# M0564AE_v1 register map
File version: 1.0
Registers are 32-bit, read-write, reset 0x0 unless marked. A register's access mark holds for its fields unless they carry their own. Offsets are from the block's base; [hi:lo] are bit positions.

## SC0 — SC Register Map
Base 0x40190000
Same registers: SC1 0x40194000
0x00 SC_DAT reset not defined — SC Receive/Transmit Holding Buffer Register
  [7:0] DAT — Receive/Transmit Holding Buffer. Write Operation: By writing data to DAT, the SC will send out an 8-bit data. Read Operation: By reading DAT, the SC will return an 8-bit received data. Note: If SCEN (SC_CTL[0]) is not enabled, DAT cannot be programmed.
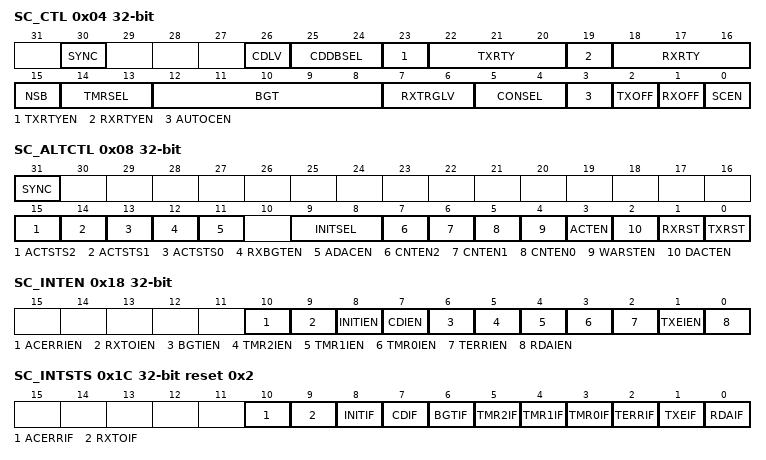
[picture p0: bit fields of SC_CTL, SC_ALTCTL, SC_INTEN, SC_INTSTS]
0x04 SC_CTL — SC Control Register
  [30] SYNC ro — SYNC Flag Indicator (Read Only). Due to synchronization, user should check this bit before writing a new value to RXRTY and TXRTY fields.
    0=Synchronizing is completion, user can write new data to RXRTY and TXRTY; 1=Last value is synchronizing
  [26] CDLV — Card Detect Level Selection. Note: User must select card detect level before Smart Card controller enabled.
    0=When hardware detects the card detect pin (SC_CD) from high to low, it indicates a card is detected; 1=When hardware detects the card detect pin (SC_CD) from low to high, it indicates a card is detected
  [25:24] CDDBSEL — Card Detect De-bounce Selection. This field indicates the card detect de-bounce selection. Other configurations are reserved.
    0=De-bounce sample card insert once per 384 (128 * 3) SC modue clocks and de-bounce sample card removal once per 128 SC modue clocks
  [23] TXRTYEN — TX Error Retry Enable Bit. This bit enables transmitter retry function when parity error has occurred.
    0=TX error retry function Disabled; 1=TX error retry function Enabled
  [22:20] TXRTY — TX Error Retry Count Number. This field indicates the maximum number of transmitter retries that are allowed when parity error has occurred. Note1: The real retry number is TXRTY + 1, so 8 is the maximum retry number. Note2: This field cannot be changed when TXRTYEN enabled. The change flow is to disable TXRTYEN first and then fill in new retry value.
  [19] RXRTYEN — RX Error Retry Enable Bit. This bit enables receiver retry function when parity error has occurred. Note: User must fill in the RXRTY value before enabling this bit.
    0=RX error retry function Disabled; 1=RX error retry function Enabled
  [18:16] RXRTY — RX Error Retry Count Number. This field indicates the maximum number of receiver retries that are allowed when parity error has occurred. Note1: The real retry number is RXRTY + 1, so 8 is the maximum retry number. Note2: This field cannot be changed when RXRTYEN enabled. The change flow is to disable RXRTYEN first and then fill in new retry value.
  [15] NSB — Stop Bit Length. This field indicates the length of stop bit. Note1: The default stop bit length is 2. SC and UART adopts NSB to program the stop bit length. Note2: In UART mode, RX can receive the data sequence in 1 stop bit or 2 stop bits with NSB is set to 0.
    0=The stop bit length is 2 ETU; 1=The stop bit length is 1 ETU
  [14:13] TMRSEL — Timer Channel Selection. Other configurations are reserved
    0=All internal timer function Disabled; 3=Internal 24-bit Timer0 and two 8-bit Timer0 and Timer1 are enabled. User can configure them by setting SC_TMRCTL0[23:0], SC_TMRCTL1[7:0] and SC_TMRCTL2[7:0]
  [12:8] BGT — Block Guard Time (BGT). Note: The real block guard time is BGT + 1.
  [7:6] RXTRGLV — Rx Buffer Trigger Level. When the number of bytes in the receiving buffer equals the RXTRGLV, the RDAIF (SC_INTSTS[0]) will be set. If RDAIEN (SC_INTEN[0]) is enabled, an interrupt signal will be generated to inform CPU.
    0=Rx Buffer Trigger Level with 01 bytes; 1=Rx Buffer Trigger Level with 02 bytes; 2=Rx Buffer Trigger Level with 03 bytes
  [5:4] CONSEL — Convention Selection. Note: If AUTOCEN (SC_CTL[3]) is enabled, this field is ignored.
    0=Direct convention; 3=Inverse convention
  [3] AUTOCEN — Auto Convention Enable Bit. This bit is used to enable auto convention function. Note1: If user enables auto convention function, the setting step must be done before Answer to Reset (ATR) state and the first data must be 0x3B or 0x3F. After hardware received first data and stored it at buffer, hardware will decided the convention and change the CONSEL (SC_CTL[5:4]) bits automatically when received first data is 0x3B or 0x3F. If received first byte is 0x3B, TS is direct convention, CONSEL (SC_CTL[5:4]) will be set to 00 automatically, otherwise the TS is inverse convention, and CONSEL (SC_CTL[5:4]) will be set to 11. Note2: If the first data is not 0x3B or 0x3F, hardware will set ACERRIF (SC_INTSTS[10]) and generate an interrupt signal to inform CPU when ACERRIEN (SC_INTEN[10]) is enabled.
    0=Auto-convention Disabled; 1=Auto-convention Enabled
  [2] TXOFF — TX Transition Disable Bit. This bit is used to disable Tx transmit function.
    0=The transceiver Enabled; 1=The transceiver Disabled
  [1] RXOFF — RX Transition Disable Bit. This bit is used to disable Rx receive function. Note: If AUTOCEN (SC_CTL[3]) is enabled, this field is ignored.
    0=The receiver Enabled; 1=The receiver Disabled
  [0] SCEN — SC Controller Enable Bit. Set this bit to 1 to enable SC operation function. Note: SCEN must be set to 1 before filling in other SC registers, or smart card will not work properly.
    0=SC will force all transition to IDLE state; 1=SC controller is enabled and all function can work correctly
0x08 SC_ALTCTL — SC Alternate Control Register
  [31] SYNC ro — SYNC Flag Indicator (Read Only). Due to synchronization, user should check this bit when writing a new value to SC_ALTCTL register.
    0=Synchronizing is completion, user can write new data to SC_ALTCTL register; 1=Last value is synchronizing
  [15] ACTSTS2 ro — Internal Timer2 Active Status (Read Only). This bit indicates the timer counter status of timer2. Note: Timer2 is active does not always mean timer2 is counting the CNT (SC_TMRCTL2[7:0]).
    0=Timer2 is not active; 1=Timer2 is active
  [14] ACTSTS1 ro — Internal Timer1 Active Status (Read Only). This bit indicates the timer counter status of timer1. Note: Timer1 is active does not always mean timer1 is counting the CNT (SC_TMRCTL1[7:0]).
    0=Timer1 is not active; 1=Timer1 is active
  [13] ACTSTS0 ro — Internal Timer0 Active Status (Read Only). This bit indicates the timer counter status of timer0. Note: Timer0 is active does not always mean timer0 is counting the CNT (SC_TMRCTL0[23:0]).
    0=Timer0 is not active; 1=Timer0 is active
  [12] RXBGTEN — Receiver Block Guard Time Function Enable Bit. This bit enables the receiver block guard time function.
    0=Receiver block guard time function Disabled; 1=Receiver block guard time function Enabled
  [11] ADACEN — Auto Deactivation When Card Removal. This bit is usde for enable hardware auto deactivation when smart card is removed. Note: When the card is removed, hardware will stop any process and then do deactivation sequence if this bit is set. If auto deactivation process completes, hardware will set INITIF (SC_INTSTS[8]) also.
    0=Auto deactivation Disabled; 1=Auto deactivation Enabled
  [9:8] INITSEL — Initial Timing Selection. This fields indicates the initial timing of hardware activation, warm-reset or deactivation. The unit of initial timing is SC module clock. Activation: refer to SC Activation Sequence in Figure 6.154. Warm-reset: refer to Warm-Reset Sequence in Figure 6.155. Deactivation: refer to Deactivation Sequence in Figure 6.156. Note: When setting activation and warm reset in Timer0 operation mode 0011, it may have deviation at most 128 SC module clock cycles.
  [7] CNTEN2 — Internal Timer2 Start Enable Bit. This bit enables Timer 2 to start counting. User can fill 0 to stop count and set 1 to reload and start count. The counter unit is ETU base. Note3: If SCEN (SC_CTL[0]) is not enabled, this filed cannot be programmed.
    0=Stop counting; 1=Start counting
  [6] CNTEN1 — Internal Timer1 Start Enable Bit. This bit enables Timer 1 to start counting. User can fill 0 to stop count and set 1 to reload and start count. The counter unit is ETU base. Note3: If SCEN (SC_CTL[0]) is not enabled, this filed cannot be programmed.
    0=Stop counting; 1=Start counting
  [5] CNTEN0 — Internal Timer0 Start Enable Bit. This bit enables Timer 0 to start counting. User can fill 0 to stop count and set 1 to reload and start count. The counter unit is ETU base. Note3: If SCEN (SC_CTL[0]) is not enabled, this filed cannot be programmed.
    0=Stop counting; 1=Start counting
  [4] WARSTEN — Warm Reset Sequence Generator Enable Bit. This bit enables SC controller to initiate the card by warm reset sequence. Note1: When the warm reset sequence completed, this bit will be cleared automatically and the INITIF (SC_INTSTS[8]) will be set to 1. Note2: This field will be cleared by set TXRST (SC_ALTCTL[0]) or RXRST (SC_ALTCTL[1]). Thus, do not fill in WARSTEN, TXRST or RXRST at the same time. Note3: If SCEN (SC_CTL[0]) is not enabled, this filed cannot be programmed.
    0=No effect; 1=Warm reset sequence generator Enabled
  [3] ACTEN — Activation Sequence Generator Enable Bit. This bit enables SC controller to initiate the card by activation sequence. Note1: When the activation sequence completed, this bit will be cleared automatically and the INITIF (SC_INTSTS[8]) will be set to 1. Note2: This field will be cleared by set TXRST (SC_ALTCTL[0]) or RXRST (SC_ALTCTL[1]). Thus, do not fill in ACTEN, TXRST or RXRST at the same time. Note3: If SCEN (SC_CTL[0]) is not enabled, this filed cannot be programmed.
    0=No effect; 1=Activation sequence generator Enabled
  [2] DACTEN — Deactivation Sequence Generator Enable Bit. This bit enables SC controller to initiate the card by deactivation sequence. Note1: When the deactivation sequence completed, this bit will be cleared automatically and the INITIF (SC_INTSTS[8]) will be set to 1. Note2: This field will be cleared by set TXRST (SC_ALTCTL[0]) or RXRST (SC_ALTCTL[1]). Thus, do not fill in DACTEN, TXRST or RXRST at the same time. Note3: If SCEN (SC_CTL[0]) is not enabled, this filed cannot be programmed.
    0=No effect; 1=Deactivation sequence generator Enabled
  [1] RXRST — RX Software Reset. When RXRST is set, all the bytes in the receive buffer and Rx internal state machine will be cleared. Note: This bit will be auto cleared after reset is complete.
    0=No effect; 1=Reset the Rx internal state machine and pointers
  [0] TXRST — TX Software Reset. When TXRST is set, all the bytes in the transmit buffer and Tx internal state machine will be cleared. Note: This bit will be auto cleared after reset is complete.
    0=No effect; 1=Reset the Tx internal state machine and pointers
0x0C SC_EGT — SC Extra Guard Time Register
  [7:0] EGT — Extra Guard Time. This field indicates the extra guard time value. Note: The extra guard time unit is ETU base.
0x10 SC_RXTOUT — SC Receive Buffer Time-out Counter Register
  [8:0] RFTM — SC Receiver FIFO Time-out Counter. The time-out down counter resets and starts counting whenever the Rx buffer received a new data. Once the counter decrease to 1 and no new data is received or CPU does not read data by reading DAT (SC_DAT[7:0]), a receiver time-out flag RXTOIF (SC_INTSTS[9]) will be set, and hardware will generate an interrupt signal to inform CPU when RXTOIEN (SC_INTEN[9]) is enabled. Note1: The counter unit is ETU based and the interval of time-out is (RFTM + 0.5) ETU time. Note2: Filling in all 0 to this field will disable this function.
0x14 SC_ETUCTL reset 0x173 — SC Element Time Unit Control Register
  [11:0] ETURDIV — ETU Rate Divider. The field is used for define ETU time unit. The real ETU time unit is (ETURDIV + 1) * SC clock time. Note: User can configure this field, but this field must be greater than 0x004.
0x18 SC_INTEN — SC Interrupt Enable Control Register
  [10] ACERRIEN — Auto Convention Error Interrupt Enable Bit. This field is used to enable auto-convention error interrupt.
    0=Auto-convention error interrupt Disabled; 1=Auto-convention error interrupt Enabled
  [9] RXTOIEN — Receiver Buffer Time-out Interrupt Enable Bit. This field is used to enable receiver buffer time-out interrupt.
    0=Receiver buffer time-out interrupt Disabled; 1=Receiver buffer time-out interrupt Enabled
  [8] INITIEN — Initial End Interrupt Enable Bit
    0=Initial end interrupt Disabled; 1=Initial end interrupt Enabled
  [7] CDIEN — Card Detect Interrupt Enable Bit. This field is used to enable card detect interrupt. The card detect status is CDPINSTS (SC_STATUS[13]). Note: Either cared insert or card remove event will generate crad detect event.
    0=Card detect interrupt Disabled; 1=Card detect interrupt Enabled
  [6] BGTIEN — Block Guard Time Interrupt Enable Bit. This field is used to enable block guard time interrupt in receive direction. Note: This bit is valid only for receive direction block guard time.
    0=Block guard time interrupt Disabled; 1=Block guard time interrupt Enabled
  [5] TMR2IEN — Timer2 Interrupt Enable Bit. This field is used to enable Timer2 interrupt function.
    0=Timer2 interrupt Disabled; 1=Timer2 interrupt Enabled
  [4] TMR1IEN — Timer1 Interrupt Enable Bit. This field is used to enable the Timer1 interrupt function.
    0=Timer1 interrupt Disabled; 1=Timer1 interrupt Enabled
  [3] TMR0IEN — Timer0 Interrupt Enable Bit. This field is used to enable Timer0 interrupt function.
    0=Timer0 interrupt Disabled; 1=Timer0 interrupt Enabled
  [2] TERRIEN — Transfer Error Interrupt Enable Bit. This field is used to enable transfer error interrupt. The transfer error status is at SC_STATUS which includes receiver break error BEF (SC_STATUS[6]), frame error FEF (SC_STATUS[5]), parity error PEF (SC_STATUS[4]), receive buffer overflow error RXOV (SC_STATUS[0]), transmit buffer overflow error TXOV (SC_STATUS[8]), receiver retry over limit error RXOVERR (SC_STATUS[22]) or transmitter retry over limit error TXOVERR (SC_STATUS[30]).
    0=Transfer error interrupt Disabled; 1=Transfer error interrupt Enabled
  [1] TXEIEN — Transmit Buffer Empty Interrupt Enable Bit. This field is used to enable transmit buffer empty interrupt.
    0=Transmit buffer empty interrupt Disabled; 1=Transmit buffer empty interrupt Enabled
  [0] RDAIEN — Receive Data Reach Interrupt Enable Bit. This field is used to enable received data bytes in Rx buffer reaching trigger level RXTRGLV (SC_CTL[7:6]) interrupt.
    0=Received data bytes in Rx buffer reach trigger level interrupt Disabled; 1=Received data bytes in Rx buffer reach trigger level interrupt Enabled
0x1C SC_INTSTS reset 0x2 — SC Interrupt Status Register
  [10] ACERRIF — Auto Convention Error Interrupt Status Flag. This field indicates auto convention sequence error. Note: This bit can be cleared by writing 1 to it.
    0=Received TS at ATR state is 0x3B or 0x3F; 1=Received TS at ATR state is neither 0x3B nor 0x3F
  [9] RXTOIF ro — Receive Buffer Time-out Interrupt Status Flag (Read Only). This field is used for indicate receive buffer time-out interrupt status flag. Note: This bit is read only, user must read all receive buffer remaining data by reading DAT (SC_DAT[7:0]) to clear it.
    0=Receive buffer time-out interrupt did not occur; 1=Receive buffer time-out interrupt occurred
  [8] INITIF — Initial End Interrupt Status Flag. This field is used for activation (ACTEN (SC_ALTCTL[3])), deactivation (DACTEN (SC_ALTCTL[2])) and warm reset (WARSTEN (SC_ALTCTL[4])) sequence interrupt status flag. Note: This bit can be cleared by writing 1 to it.
    0=Initial sequence is not complete; 1=Initial sequence is completed
  [7] CDIF ro — Card Detect Interrupt Status Flag (Read Only). This field is used for card detect interrupt status flag. The actual card detect status is in CINSERT (SC_STATUS[12]) and CREMOVE (SCn_STATUS[11]). Note1: This bit is read only, and will be cleared after CINSERT or CREMOVE status has been cleared. Note2: Either cared insert or card remove event will generate crad detect event.
    0=Card detect event did not occur; 1=Card detect event occurred
  [6] BGTIF
    0=Block guard time interrupt did not occur; 1=Block guard time interrupt occurred
  [5] TMR2IF — Timer2 Interrupt Status Flag. This field is used for Timer2 interrupt status flag. Note: This bit can be cleared by writing 1 to it.
    0=Timer2 interrupt did not occur; 1=Timer2 interrupt occurred
  [4] TMR1IF — Timer1 Interrupt Status Flag. This field is used for Timer1 interrupt status flag. Note: This bit can be cleared by writing 1 to it.
    0=Timer1 interrupt did not occur; 1=Timer1 interrupt occurred
  [3] TMR0IF — Timer0 Interrupt Status Flag. This field is used for Timer0 interrupt status flag. Note: This bit can be cleared by writing 1 to it.
    0=Timer0 interrupt did not occur; 1=Timer0 interrupt occurred
  [2] TERRIF — Transfer Error Interrupt Status Flag. This field is used for indicate transfer error interrupt status flag. The transfer error status is at SC_STATUS which includes receiver break error BEF (SC_STATUS[6]), frame error FEF (SC_STATUS[5]), parity error PEF (SC_STATUS[4]), receive buffer overflow error RXOV (SC_STATUS[0]), transmit buffer overflow error TXOV (SC_STATUS[8]), receiver retry over limit error RXOVERR (SC_STATUS[22]) or transmitter retry over limit error TXOVERR (SC_STATUS[30]). Note1: This field is the status flag of BEF, FEF, PEF, RXOV, TXOV, RXOVERR or TXOVERR. Note2: This bit can be cleared by writing 1 to it.
    0=Transfer error interrupt did not occur; 1=Transfer error interrupt occurred
  [1] TXEIF ro — Transmit Buffer Empty Interrupt Status Flag (Read Only). This field is used for transmit buffer empty interrupt status flag. Note: This bit is read only. If user wants to clear this bit, user must write data to DAT (SC_DAT[7:0]) and then this bit will be cleared automatically.
    0=Transmit buffer is not empty; 1=Transmit buffer is empty
  [0] RDAIF ro — Receive Data Reach Interrupt Status Flag (Read Only). This field is used for received data bytes in Rx buffer reaching trigger level RXTRGLV (SC_CTL[7:6]) interrupt status flag. Note: This bit is read only. If user reads data from DAT (SC_DAT[7:0]) and remains receiver buffer data byte number is less than RXTRGLV, this bit will be cleared automatically.
    0=Number of receive buffer is less than RXTRGLV setting; 1=Number of receive buffer data equals the RXTRGLV setting
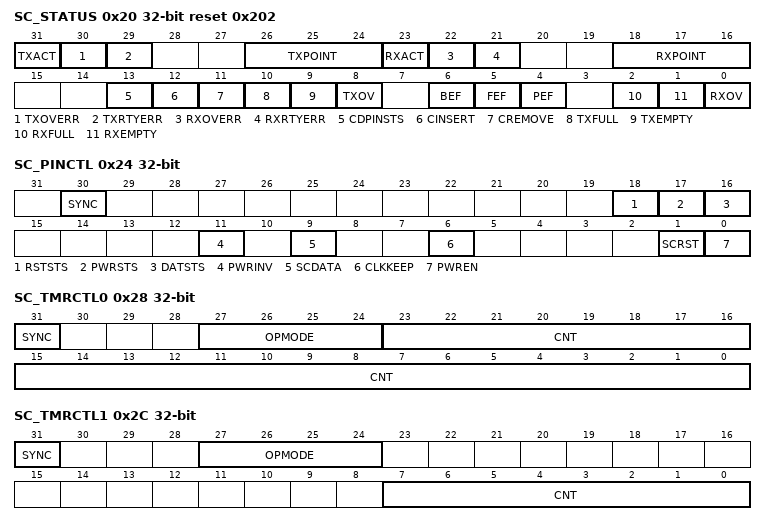
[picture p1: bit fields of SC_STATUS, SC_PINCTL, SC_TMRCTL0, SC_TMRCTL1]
0x20 SC_STATUS reset 0x202 (reset mask 0xFFFF0FFF) — SC Transfer Status Register
  [31] TXACT ro — Transmit in Active Status Flag (Read Only). This bit indicates Tx transmit status.
    0=This bit is cleared automatically when Tx transfer is finished or the last byte transmission has completed; 1=Transmit is active or the STOP bit of last byte has not been transmitted when Tx transfer is in active
  [30] TXOVERR — Transmitter over Retry Error. This bit is used for transmitter retry counts over than retry number limitation. Note: This bit can be cleared by writing 1 to it.
    0=Transmitter retries counts is not over than TXRTY (SC_CTL[22:20]) + 1; 1=Transmitter retries counts over than TXRTY (SC_CTL[22:20]) + 1
  [29] TXRTYERR — Transmitter Retry Error. This bit is used for indicate transmitter error retry and set by hardware.. Note1: This bit can be cleared by writing 1 to it. Note2: This bit is a flag and cannot generate any interrupt signal to CPU.
    0=No Tx retry transfer; 1=Tx has any error and retries transfer
  [26:24] TXPOINT ro — Transmit Buffer Pointer Status (Read Only). This field indicates the Tx buffer pointer status. When CPU writes data into DAT (SC_DAT[7:0]), TXPOINT increases one. When one byte of Tx buffer is transferred to Transmitter Shift Register, TXPOINT decreases one.
  [23] RXACT ro — Receiver in Active Status Flag (Read Only). This bit indicates Rx transfer status.
    0=This bit is cleared automatically when Rx transfer is finished; 1=This bit is set by hardware when Rx transfer is in active
  [22] RXOVERR — Receiver over Retry Error. This bit is used for indicate receiver retry counts over than retry number limitation. Note1: This bit can be cleared by writing 1 to it. Note2: If user enables receiver retries function by setting RXRTYEN (SC_CTL[19]), the PEF (SC_STATUS[4]) bit will not set.
    0=Receiver retries counts is not over than RXRTY (SC_CTL[18:16]) + 1; 1=Receiver retries counts over than RXRTY (SC_CTL[18:16]) + 1
  [21] RXRTYERR — Receiver Retry Error. This bit is used for indicate receiver error retry and set by hardware. Note1: This bit can be cleared by writing 1 to it. Note2: This bit is a flag and cannot generate any interrupt signal to CPU. Note3: If user enables receiver retries function by setting RXRTYEN (SC_CTL[19]), the PEF (SC_STATUS[4]) bit will not set.
    0=No Rx retry transfer; 1=Rx has any error and retries transfer
  [18:16] RXPOINT ro — Receive Buffer Pointer Status (Read Only). This field indicates the Rx buffer pointer status. When SC controller receives one byte from external device, RXPOINT increases one. When one byte in Rx buffer is read by reading DAT (SC_DAT[7:0]), RXPOINT decreases one.
  [13] CDPINSTS ro — Card Detect Pin Status (Read Only). This bit is the pin status of SC_CD.
    0=The SC_CD pin state at low; 1=The SC_CD pin state at high
  [12] CINSERT — Card Insert Status of SC_CD Pin. This bit is set whenever card has been inserted. Note1: This bit can be cleared by writing 1 to it. Note2: The card detect function will start after SCEN (SC_CTL[0]) is set.
    0=No effect; 1=Card insert
  [11] CREMOVE — Card Removal Status of SCn_CD Pin. This bit is set whenever card has been removal. Note1: This bit can be cleared by writing 1 to it. Note2: Card detect function will start after SCEN (SC_CTL[0]) is set.
    0=No effect; 1=Card removed
  [10] TXFULL ro — Transmit Buffer Full Status Flag (Read Only). This bit indicates Tx buffer is full or not.
    0=Tx buffer count is less than 4; 1=Tx buffer count equals to 4
  [9] TXEMPTY ro — Transmit Buffer Empty Status Flag (Read Only). This bit indicates TX buffer is empty or not. Note: This bit will be cleared when writing data into DAT (SC_DAT[7:0]).
    0=Tx buffer is not empty; 1=Tx buffer is empty, it means the last byte of Tx buffer has been transferred to Transmitter Shift Register
  [8] TXOV — Transmit Overflow Error Interrupt Status Flag. This bit is set when Tx buffer overflow. Note: This bit can be cleared by writing 1 to it.
    0=Tx buffer is not overflow; 1=Tx buffer is overflow, it means an additional write operation to DAT (SC_DAT[7:0]) when Tx buffer is already full
  [6] BEF — Receiver Break Error Status Flag. This bit is set to logic 1 whenever the received data input (Rx) held in the 'spacing state' (logic 0) is longer than a full word transmission time (that is, the total time of 'start bit' + 'data bits' + 'parity bit' + 'stop bits'). Note1: This bit can be cleared by writing 1 to it. Note2: If user sets receiver retries function by setting RXRTYEN (SCn_CTL[19]), hardware will not set this flag.
    0=Receiver break error flag did not occur; 1=Receiver break error flag occurred
  [5] FEF — Receiver Frame Error Status Flag. This bit is set to logic 1 whenever the received character does not have a valid 'stop bit' (that is, the stop bit following the last data bit or parity bit is detected as logic 0). Note1: This bit can be cleared by writing 1 to it. Note2: If user sets receiver retries function by setting RXRTYEN (SC_CTL[19]), hardware will not set this flag.
    0=Receiver frame error flag did not occur; 1=Receiver frame error flag occurred
  [4] PEF — Receiver Parity Error Status Flag. This bit is set to logic 1 whenever the received character does not have a valid 'parity bit'. Note1: This bit can be cleared by writing 1 to it. Note2: If user sets receiver retries function by setting RXRTYEN (SC_CTL[19]), hardware will not set this flag.
    0=Receiver parity error flag did not occur; 1=Receiver parity error flag occurred
  [2] RXFULL ro — Receive Buffer Full Status Flag (Read Only). This bit indicates Rx buffer is full or not.
    0=Rx buffer count is less than 4; 1=Rx buffer count equals to 4
  [1] RXEMPTY ro — Receive Buffer Empty Status Flag (Read Only). This bit indicates Rx buffer is empty or not.
    0=Rx buffer is not empty; 1=Rx buffer is empty, it means the last byte in Rx buffer has been read from DAT (SC_DAT[7:0])
  [0] RXOV — Receive Overflow Error Status Flag. This bit is set when Rx buffer overflow. Note: This bit can be cleared by writing 1 to it.
    0=Rx buffer is not overflow; 1=Rx buffer is overflow when the number of received bytes is greater than Rx buffer size (4 bytes)
0x24 SC_PINCTL (reset mask 0xFFFFFF0F) — SC Pin Control State Register
  [30] SYNC ro — SYNC Flag Indicator (Read Only). Due to synchronization, user should check this bit when writing a new value to SC_PINCTL register.
    0=Synchronizing is completion, user can write new data to SC_PINCTL register; 1=Last value is synchronizing
  [18] RSTSTS ro — SC_RST Pin Status (Read Only). This bit is the pin status of SC_RST.
    0=SC_RST pin is low; 1=SC_RST pin is high
  [17] PWRSTS ro — SC_PWR Pin Status (Read Only). This bit is the pin status of SC_PWR.
    0=SC_PWR pin to low; 1=SC_PWR pin to high
  [16] DATSTS ro — SC_DATA Pin Status (Read Only)
    0=The SC_DATA pin status is low; 1=The SC_DATA pin status is high
  [11] PWRINV — SC_PWR Pin Inverse. This bit is used for inverse the SC_PWR pin. There are four kinds of combination for SC_PWR pin setting by PWRINV (SC_PINCTL[11]) and PWREN (SC_PINCTL[0]). And all conditions as below list. Note: User must select PWRINV (SC_PINCTL[11]) before smart card is enabled by SCEN (SC_CTL[0]).
  [9] SCDATA — SC_DATA Pin Signal. This bit is the signal status of SC_DATA but user can also drive SC_DATA pin to high or low by control this bit. Write this bit can drive SC_RST pin. Note: When SC is at activation, warm reset or deactivation mode, this bit will be changed automatically. Thus, do not fill in this field when SC is in these modes.
    0=Drive SC_DATA pin to low. SC_DATA signal status is low; 1=Drive SC_DATA pin to high. SC_DATA signal status is high
  [6] CLKKEEP — SC Clock Enable Bit. Note: When operating in activation, warm reset or deactivation mode, this bit will be changed automatically. Thus, do not fill in this field when operating in these modes.
    0=SC clock generation Disabled; 1=SC clock always keeps free running
  [1] SCRST — SC_RST Pin Signal. This bit is the signal status of SC_RST but user can drive SC_RST pin to high or low by control this bit. Write this bit can drive SC_RST pin. Note: When operating at activation, warm reset or deactivation mode, this bit will be changed automatically. Thus, do not fill in this field when operating in these modes.
    0=Drive SC_RST pin to low. SC_RST signal status is low; 1=Drive SC_RST pin to high. SC_RST signal status is high
  [0] PWREN — SC_PWR Pin Signal. User can set PWRINV (SC_PINCTL[11]) and PWREN (SC_PINCTL[0]) to decide SC_PWR pin is in high or low level. Write this bit can drive SC_PWR pin. Refer PWRINV (SC_PINCTL[11]) description for programming SC_PWR pin voltage level. Read this bit to get SC_PWR signal status. Note: When operating at activation, warm reset or deactivation mode, this bit will be changed automatically. Thus, do not fill in this field when operating in these modes
    0=SC_PWR signal status is low; 1=SC_PWR signal status is high
0x28 SC_TMRCTL0 — SC Timer0 Control Register
  [31] SYNC ro — SYNC Flag Indicator (Read Only). Due to synchronization, user should check this bit when writing a new value to SC_TMRCTL0 register.
    0=Synchronizing is completion, user can write new data to SC_TMRCTL0 register; 1=Last value is synchronizing
  [27:24] OPMODE — Timer 0 Operation Mode Selection. This field indicates the internal 24-bit Timer0 operation selection. Refer to Table 6.1528 for programming Timer0.
  [23:0] CNT — Timer 0 Counter Value. This field indicates the internal Timer0 counter values. Note: Unit of Timer0 counter is ETU base.
0x2C SC_TMRCTL1 — SC Timer1 Control Register
  [31] SYNC ro — SYNC Flag Indicator (Read Only). Due to synchronization, user should check this bit when writing a new value to SC_TMRCTL1 register.
    0=Synchronizing is completion, user can write new data to SC_TMRCTL1 register; 1=Last value is synchronizing
  [27:24] OPMODE — Timer 1 Operation Mode Selection. This field indicates the internal 8-bit Timer1 operation selection. Refer to Table 6.1528 for programming Timer1.
  [7:0] CNT — Timer 1 Counter Value. This field indicates the internal Timer1 counter values. Note: Unit of Timer1 counter is ETU base.
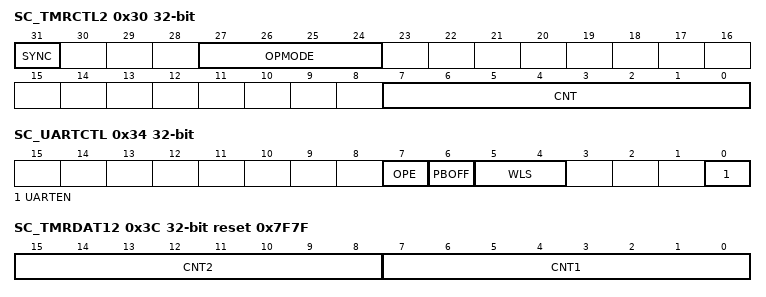
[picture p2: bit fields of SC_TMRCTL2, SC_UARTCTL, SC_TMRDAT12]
0x30 SC_TMRCTL2 — SC Timer2 Control Register
  [31] SYNC ro — SYNC Flag Indicator (Read Only). Due to synchronization, user should check this bit when writing a new value to SC_TMRCTL2 register.
    0=Synchronizing is completion, user can write new data to SC_TMRCTL2 register; 1=Last value is synchronizing
  [27:24] OPMODE — Timer 2 Operation Mode Selection. This field indicates the internal 8-bit Timer2 operation selection. Refer to Table 6.1528 for programming Timer2.
  [7:0] CNT — Timer 2 Counter Value. This field indicates the internal Timer2 counter values. Note: Unit of Timer2 counter is ETU base.
0x34 SC_UARTCTL — SC UART Mode Control Register
  [7] OPE — Odd Parity Enable Bit. This is used for odd/even parity selection. Note: This bit has effect only when PBOFF bit is 0.
    0=Even number of logic 1's are transmitted or check the data word and parity bits in receiving mode; 1=Odd number of logic 1's are transmitted or check the data word and parity bits in receiving mode
  [6] PBOFF — Parity Bit Disable Control. This bit is used to disable parity check function. Note: In smart card mode, this bit must be 0 (default setting is with parity bit).
    0=Parity bit is generated or checked between the 'last data word bit' and 'stop bit' of the serial data; 1=Parity bit is not generated (transmitting data) or checked (receiving data) during transfer
  [5:4] WLS — Word Length Selection. This field is used to select UART data transfer length. Note: In smart card mode, this field must be 00.
    0=Word length is 8 bits; 1=Word length is 7 bits; 2=Word length is 6 bits; 3=Word length is 5 bits
  [0] UARTEN — UART Mode Enable Bit. Set this bit to enable UART mode function. Note3: When UART mode is enabled, hardware will generate a reset SC event to reset FIFO and internal state machine.
    0=Smart Card mode; 1=UART mode
0x38 SC_TMRDAT0 ro reset 0x7FF — SC Timer0 Current Data Register
  [23:0] CNT0 — Timer0 Current Data Value (Read Only). This field indicates the current counter values of Timer0.
0x3C SC_TMRDAT12 ro reset 0x7F7F — SC Timer1/2 Current Data Register
  [15:8] CNT2 — Timer2 Current Data Value (Read Only). This field indicates the current counter values of Timer2.
  [7:0] CNT1 — Timer1 Current Data Value (Read Only). This field indicates the current counter values of Timer1.
0x4C SC_ACTCTL — SC Activation Control Register
  [4:0] T1EXT — T1 Extend Time of Hardware Activation. This field provide the configurable cycles to extend the activation time T1 period. Please refer to SC activation sequence in Figure 6.154. The cycle scaling factor is 2048 and. Note: Setting 0 to this field conforms to the protocol ISO/IEC 7816-3.
